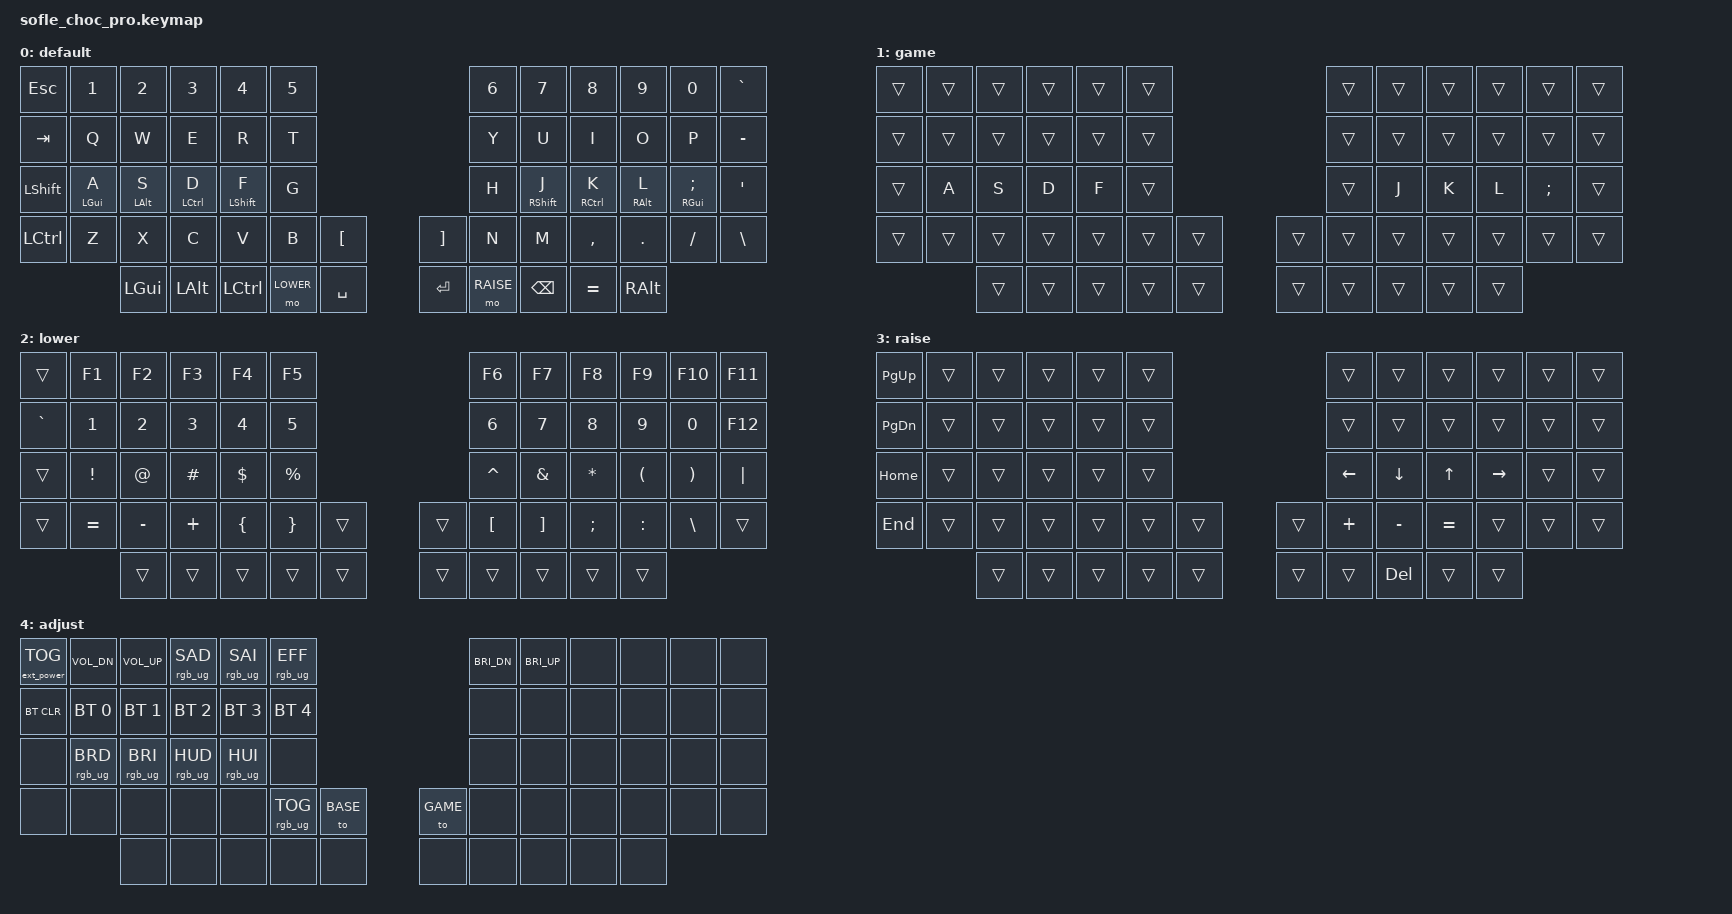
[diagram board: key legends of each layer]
/*
* Copyright (c) 2020 The ZMK Contributors
*
* SPDX-License-Identifier: MIT
*/

#include <behaviors.dtsi>
#include <dt-bindings/zmk/keys.h>
#include <dt-bindings/zmk/bt.h>
#include <dt-bindings/zmk/rgb.h>
#include <dt-bindings/zmk/ext_power.h>

#define BASE 0
#define GAME 1
#define LOWER 2
#define RAISE 3
#define ADJUST 4

// Key positions used by the positional home-row mods below (0-indexed, in the
// same order the bindings are listed). A left-hand mod only engages when a key
// on the right half or a thumb is pressed after it, and a right-hand mod only
// when a left-half/thumb key follows. This is what keeps fast same-hand rolls
// (e.g. typing "as" or "df") from misfiring as modifiers.
#define KEYS_L 0 1 2 3 4 5 12 13 14 15 16 17 24 25 26 27 28 29 36 37 38 39 40 41 42
#define KEYS_R 6 7 8 9 10 11 18 19 20 21 22 23 30 31 32 33 34 35 43 44 45 46 47 48 49
#define THUMBS 50 51 52 53 54 55 56 57 58 59

/ {

  // Activate ADJUST layer by pressing raise and lower
  conditional_layers {
    compatible = "zmk,conditional-layers";
    adjust_layer {
      if-layers = <LOWER RAISE>;
      then-layer = <ADJUST>;
    };
  };

  behaviors {
    // Home row mods — GACS order (GUI / Alt / Ctrl / Shift), positional + balanced.
    // Tap a home-row key = the letter; hold it together with an opposite-hand key
    // = the modifier. Same-hand shortcuts (e.g. Ctrl+F) use the outer-column /
    // thumb modifiers instead. Toggle the GAME layer to get plain letters back.
    hml: home_row_mod_left {
      compatible = "zmk,behavior-hold-tap";
      #binding-cells = <2>;
      flavor = "balanced";
      tapping-term-ms = <280>;
      quick-tap-ms = <175>;
      require-prior-idle-ms = <150>;
      hold-trigger-key-positions = <KEYS_R THUMBS>;
      hold-trigger-on-release;
      bindings = <&kp>, <&kp>;
    };

    hmr: home_row_mod_right {
      compatible = "zmk,behavior-hold-tap";
      #binding-cells = <2>;
      flavor = "balanced";
      tapping-term-ms = <280>;
      quick-tap-ms = <175>;
      require-prior-idle-ms = <150>;
      hold-trigger-key-positions = <KEYS_L THUMBS>;
      hold-trigger-on-release;
      bindings = <&kp>, <&kp>;
    };
  };

  keymap {
    compatible = "zmk,keymap";

    default_layer {
      display-name = "default";
      // ------------------------------------------------------------------------------------------------------------
      // |  ESC  |  1  |  2  |  3   |  4   |  5   |                   |  6   |  7    |  8    |  9   |   0   |   `   |
      // |  TAB  |  Q  |  W  |  E   |  R   |  T   |                   |  Y   |  U    |  I    |  O   |   P   |  - _  |
      // |  SHIFT| A/⌘ | S/⌥ | D/⌃  | F/⇧  |  G   |                   |  H   | J/⇧   | K/⌃   | L/⌥  |  ;/⌘  |   '   |
      // | CTRL  |  Z  |  X  |  C   |  V   |  B   |  [     |  | ]     |  N   |  M    |  ,    |  .   |   /   | \ |   |
      //               | GUI | ALT  | CTRL | LOWER|  SPACE |  | ENTER | RAISE| ERASE | =  +  | ALTGR|
      bindings = <
        &kp ESC   &kp N1 &kp N2   &kp N3   &kp N4    &kp N5                           &kp N6 &kp N7    &kp N8    &kp N9   &kp N0   &kp GRAVE
        &kp TAB   &kp Q  &kp W    &kp E    &kp R     &kp T                            &kp Y  &kp U     &kp I     &kp O    &kp P    &kp MINUS
        &kp LSHFT &hml LGUI A &hml LALT S &hml LCTRL D &hml LSHFT F &kp G             &kp H  &hmr RSHFT J &hmr RCTRL K &hmr RALT L &hmr RGUI SEMI &kp SQT
        &kp LCTRL &kp Z  &kp X    &kp C    &kp V     &kp B   &kp LBKT   &kp RBKT      &kp N  &kp M     &kp COMMA &kp DOT  &kp FSLH &kp BACKSLASH
        &kp LGUI &kp LALT &kp LCTRL &mo LOWER  &kp SPACE                          &kp RET    &mo RAISE  &kp BSPC  &kp EQUAL &kp RALT
      >;

      sensor-bindings = <&inc_dec_kp C_VOL_DN C_VOL_UP &inc_dec_kp C_PREV C_NEXT>;
    };

    game_layer {
      display-name = "game";
      // ------------------------------------------------------------------------------------------------------------
      // No home row mods — plain letters everywhere so games can hold ASDF/WASD etc.
      // Only the home-row keys are overridden here; every other key falls through
      // to the base layer, so numbers, symbol/nav thumbs and encoders keep working.
      // Leave game mode with Adjust + [  (hold LOWER+RAISE, then the inner-left [ key).
      // ------------------------------------------------------------------------------------------------------------
      // |       |     |     |      |      |      |                   |      |       |       |      |       |       |
      // |       |     |     |      |      |      |                   |      |       |       |      |       |       |
      // |       |  A  |  S  |  D   |  F   |      |                   |      |   J   |   K   |  L   |   ;   |       |
      // |       |     |     |      |      |      |        |  |       |      |       |       |      |       |       |
      //               |     |      |      |      |        |  |       |      |       |       |      |
      bindings = <
        &trans    &trans &trans   &trans   &trans    &trans                           &trans &trans    &trans    &trans   &trans   &trans
        &trans    &trans &trans   &trans   &trans    &trans                           &trans &trans    &trans    &trans   &trans   &trans
        &trans    &kp A  &kp S    &kp D    &kp F     &trans                           &trans &kp J     &kp K     &kp L    &kp SEMI &trans
        &trans    &trans &trans   &trans   &trans    &trans  &trans     &trans        &trans &trans    &trans    &trans   &trans   &trans
        &trans   &trans   &trans   &trans    &trans           &trans   &trans   &trans   &trans   &trans
      >;

      sensor-bindings = <&inc_dec_kp C_VOL_DN C_VOL_UP &inc_dec_kp C_PREV C_NEXT>;
    };

    lower_layer {
      display-name = "lower";
      // ------------------------------------------------------------------------------------------------------------
      // |       |  F1 |  F2 |  F3  |  F4  |  F5  |                   |  F6  |  F7   |  F8   |  F9  |  F10  |  F11  |
      // |   `   |  1  |  2  |  3   |  4   |  5   |                   |  6   |  7    |  8    |  9   |   0   |  F12  |
      // |       |  !  |  @  |  #   |  $   |  %   |                   |  ^   |  &    |  *    |  (   |   )   |   |   |
      // |       |  =  |  -  |  +   |  {   |  }   |        |  |       |  [   |  ]    |  ;    |  :   |   \   |       |
      //               |     |      |      |      |        |  |       |      |       |       |      |
      bindings = <
        &trans    &kp F1    &kp F2    &kp F3      &kp F4    &kp F5                    &kp F6    &kp F7   &kp F8    &kp F9    &kp F10   &kp F11
        &kp GRAVE &kp N1    &kp N2    &kp N3      &kp N4    &kp N5                    &kp N6    &kp N7   &kp N8    &kp N9    &kp N0    &kp F12
        &trans    &kp EXCL  &kp AT    &kp HASH    &kp DLLR  &kp PRCNT                 &kp CARET &kp AMPS &kp ASTRK &kp LPAR  &kp RPAR  &kp PIPE
        &trans    &kp EQUAL &kp MINUS &kp PLUS &kp LBRC  &kp RBRC   &trans &trans  &kp LBKT  &kp RBKT &kp SEMI  &kp COLON &kp BSLH  &trans
        &trans    &trans      &trans    &trans     &trans &trans  &trans    &trans   &trans    &trans
      >;

      sensor-bindings = <&inc_dec_kp C_VOL_DN C_VOL_UP &inc_dec_kp C_PREV C_NEXT>;
    };

    raise_layer {
      display-name = "raise";
      // ------------------------------------------------------------------------------------------------------------
      // | PG UP |      |      |       |       |      |                |      |      |       |      |       |       |
      // | PG DN |      |      |       |       |      |                |      |      |       |      |       |       |
      // | HOME  |      |      |       |       |      |                |  <-  |  v   |   ^   |  ->  |       |       |
      // | END   |      |      |       |       |      |      |  |      |  +   |  -   |   =   |      |       |       |
      //                |      |       |       |      |      |  |      |      | DEL  |       |      |
      bindings = <
        &kp PG_UP  &trans       &trans       &trans       &trans       &trans                        &trans    &trans    &trans   &trans    &trans  &trans
        &kp PG_DN  &trans       &trans       &trans       &trans       &trans                        &trans    &trans    &trans   &trans    &trans  &trans
        &kp HOME   &trans       &trans       &trans       &trans       &trans                        &kp LEFT  &kp DOWN  &kp UP   &kp RIGHT &trans  &trans
        &kp END    &trans       &trans       &trans       &trans       &trans    &trans  &trans      &kp PLUS  &kp MINUS &kp EQUAL&trans    &trans  &trans
                      &trans     &trans       &trans       &trans       &trans                    &trans    &trans  &kp DEL     &trans    &trans
      >;

      sensor-bindings = <&inc_dec_kp C_VOL_DN C_VOL_UP &inc_dec_kp C_PREV C_NEXT>;
    };

    adjust_layer {
      // ----------------------------------------------------------------------------------------------------------------------------
      // | EXTPWR | VOL-    | VOL+    | RGB_SAD | RGB_SAI | RGB_EFF |                  | BRI- | BRI+ |       |      |       |       |
      // | BTCLR  |  BT1    |  BT2    |   BT3   |   BT4   |   BT5   |                  |      |      |       |      |       |       |
      // |        | RGB_BRD | RGB_BRI | RGB_HUD | RGB_HUI |         |                  |      |      |       |      |       |       |
      // |        |         |         |         |         | RGB_TOG | [=NORM | | ]=GAME |    |      |       |      |       |       |
      //                    |         |         |         |         |         | |      |      |      |       |      |
      // Adjust + [  ->  normal mode (home row mods ON).   Adjust + ]  ->  game mode (home row mods OFF).
      display-name = "adjust";
      bindings = <
        &ext_power EP_TOG &kp C_VOL_DN     &kp C_VOL_UP     &rgb_ug RGB_SAD &rgb_ug RGB_SAI &rgb_ug RGB_EFF                         &kp C_BRI_DN &kp C_BRI_UP &none &none &none &none
        &bt BT_CLR        &bt BT_SEL 0    &bt BT_SEL 1    &bt BT_SEL 2    &bt BT_SEL 3    &bt BT_SEL 4                            &none     &none &none &none &none &none
        &none             &rgb_ug RGB_BRD &rgb_ug RGB_BRI &rgb_ug RGB_HUD &rgb_ug RGB_HUI &none                                   &none     &none &none &none &none &none
        &none             &none           &none           &none           &none           &rgb_ug RGB_TOG  &to BASE        &to GAME  &none &none &none &none &none &none
        &none           &none           &none           &none            &none           &none  &none &none &none &none
      >;
    };
  };
};
